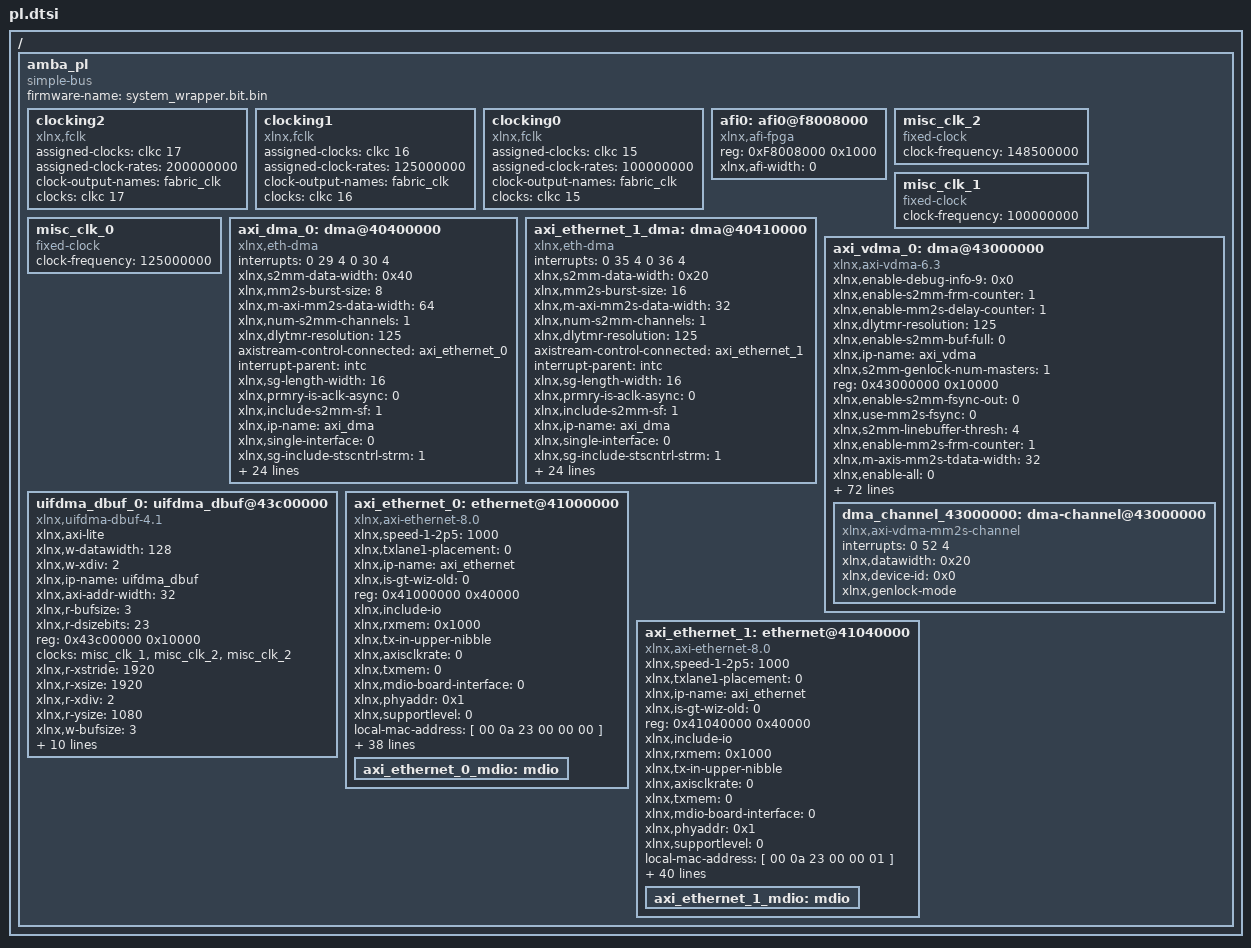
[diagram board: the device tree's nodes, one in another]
/ {
	amba_pl: amba_pl {
		ranges;
		compatible = "simple-bus";
		#address-cells = <1>;
		#size-cells = <1>;
		firmware-name = "system_wrapper.bit.bin";
		clocking2: clocking2 {
			compatible = "xlnx,fclk";
			assigned-clocks = <&clkc 17>;
			assigned-clock-rates = <200000000>;
			#clock-cells = <0>;
			clock-output-names = "fabric_clk";
			clocks = <&clkc 17>;
		};
		clocking1: clocking1 {
			compatible = "xlnx,fclk";
			assigned-clocks = <&clkc 16>;
			assigned-clock-rates = <125000000>;
			#clock-cells = <0>;
			clock-output-names = "fabric_clk";
			clocks = <&clkc 16>;
		};
		clocking0: clocking0 {
			compatible = "xlnx,fclk";
			assigned-clocks = <&clkc 15>;
			assigned-clock-rates = <100000000>;
			#clock-cells = <0>;
			clock-output-names = "fabric_clk";
			clocks = <&clkc 15>;
		};
		afi0: afi0@f8008000 {
			status = "okay";
			compatible = "xlnx,afi-fpga";
			#address-cells = <1>;
			reg = <0xF8008000 0x1000>;
			#size-cells = <0>;
			xlnx,afi-width = <0>;
		};
		misc_clk_2: misc_clk_2 {
			compatible = "fixed-clock";
			clock-frequency = <148500000>;
			#clock-cells = <0>;
		};
		misc_clk_1: misc_clk_1 {
			compatible = "fixed-clock";
			clock-frequency = <100000000>;
			#clock-cells = <0>;
		};
		misc_clk_0: misc_clk_0 {
			compatible = "fixed-clock";
			clock-frequency = <125000000>;
			#clock-cells = <0>;
		};
		axi_dma_0: dma@40400000 {
			interrupts = < 0 29 4 0 30 4 >;
			compatible = "xlnx,eth-dma";
			xlnx,s2mm-data-width = <0x40>;
			xlnx,mm2s-burst-size = <8>;
			xlnx,m-axi-mm2s-data-width = <64>;
			xlnx,num-s2mm-channels = <1>;
			xlnx,dlytmr-resolution = <125>;
			axistream-control-connected = <&axi_ethernet_0>;
			interrupt-parent = <&intc>;
			xlnx,sg-length-width = <16>;
			xlnx,prmry-is-aclk-async = <0>;
			xlnx,include-s2mm-sf = <1>;
			#dma-cells = <1>;
			xlnx,ip-name = "axi_dma";
			xlnx,single-interface = <0>;
			xlnx,sg-include-stscntrl-strm = <1>;
			xlnx,include-s2mm-dre = <1>;
			reg = <0x40400000 0x10000>;
			xlnx,addr-width = <32>;
			xlnx,include-s2mm = <1>;
			clocks = <&clkc 15>, <&clkc 15>, <&clkc 15>, <&clkc 15>;
			xlnx,s-axis-s2mm-tdata-width = <32>;
			xlnx,micro-dma = <0>;
			xlnx,increase-throughput = <0>;
			xlnx,mm2s-data-width = <0x40>;
			xlnx,addrwidth = <0x20>;
			xlnx,sg-use-stsapp-length = <1>;
			xlnx,m-axis-mm2s-tdata-width = <32>;
			xlnx,include-dre;
			xlnx,edk-iptype = "PERIPHERAL";
			xlnx,s2mm-burst-size = <16>;
			xlnx,m-axi-s2mm-data-width = <64>;
			xlnx,num-queues = /bits/ 16 <0x1>;
			xlnx,num-mm2s-channels = <1>;
			xlnx,enable-multi-channel = <0>;
			status = "okay";
			xlnx,include-mm2s-sf = <1>;
			clock-names = "m_axi_mm2s_aclk" , "m_axi_s2mm_aclk" , "m_axi_sg_aclk" , "s_axi_lite_aclk";
			axistream-connected = <&axi_ethernet_0>;
			interrupt-names = "mm2s_introut" , "s2mm_introut";
			xlnx,include-mm2s = <1>;
			xlnx,include-mm2s-dre = <1>;
			xlnx,name = "axi_dma_0";
		};
		axi_ethernet_1_dma: dma@40410000 {
			interrupts = < 0 35 4 0 36 4 >;
			compatible = "xlnx,eth-dma";
			xlnx,s2mm-data-width = <0x20>;
			xlnx,mm2s-burst-size = <16>;
			xlnx,m-axi-mm2s-data-width = <32>;
			xlnx,num-s2mm-channels = <1>;
			xlnx,dlytmr-resolution = <125>;
			axistream-control-connected = <&axi_ethernet_1>;
			interrupt-parent = <&intc>;
			xlnx,sg-length-width = <16>;
			xlnx,prmry-is-aclk-async = <0>;
			xlnx,include-s2mm-sf = <1>;
			#dma-cells = <1>;
			xlnx,ip-name = "axi_dma";
			xlnx,single-interface = <0>;
			xlnx,sg-include-stscntrl-strm = <1>;
			xlnx,include-s2mm-dre = <1>;
			reg = <0x40410000 0x10000>;
			xlnx,addr-width = <32>;
			xlnx,include-s2mm = <1>;
			clocks = <&clkc 15>, <&clkc 15>, <&clkc 15>, <&clkc 15>;
			xlnx,s-axis-s2mm-tdata-width = <32>;
			xlnx,micro-dma = <0>;
			xlnx,increase-throughput = <0>;
			xlnx,mm2s-data-width = <0x20>;
			xlnx,addrwidth = <0x20>;
			xlnx,sg-use-stsapp-length = <1>;
			xlnx,m-axis-mm2s-tdata-width = <32>;
			xlnx,include-dre;
			xlnx,edk-iptype = "PERIPHERAL";
			xlnx,s2mm-burst-size = <16>;
			xlnx,m-axi-s2mm-data-width = <32>;
			xlnx,num-queues = /bits/ 16 <0x1>;
			xlnx,num-mm2s-channels = <1>;
			xlnx,enable-multi-channel = <0>;
			status = "okay";
			xlnx,include-mm2s-sf = <1>;
			clock-names = "m_axi_mm2s_aclk" , "m_axi_s2mm_aclk" , "m_axi_sg_aclk" , "s_axi_lite_aclk";
			axistream-connected = <&axi_ethernet_1>;
			interrupt-names = "mm2s_introut" , "s2mm_introut";
			xlnx,include-mm2s = <1>;
			xlnx,include-mm2s-dre = <1>;
			xlnx,name = "axi_ethernet_1_dma";
		};
		axi_vdma_0: dma@43000000 {
			xlnx,enable-debug-info-9 = <0x0>;
			xlnx,enable-s2mm-frm-counter = <1>;
			xlnx,enable-mm2s-delay-counter = <1>;
			xlnx,dlytmr-resolution = <125>;
			xlnx,enable-s2mm-buf-full = <0>;
			xlnx,ip-name = "axi_vdma";
			xlnx,s2mm-genlock-num-masters = <1>;
			reg = <0x43000000 0x10000>;
			xlnx,enable-s2mm-fsync-out = <0>;
			xlnx,use-mm2s-fsync = <0>;
			xlnx,s2mm-linebuffer-thresh = <4>;
			xlnx,enable-mm2s-frm-counter = <1>;
			xlnx,m-axis-mm2s-tdata-width = <32>;
			xlnx,enable-all = <0>;
			xlnx,dynamic-resolution = <1>;
			xlnx,enable-s2mm-rst-out = <0>;
			interrupt-names = "mm2s_introut";
			xlnx,s2mm-sof-enable = <0x1>;
			xlnx,mm2s-genlock-num-masters = <1>;
			xlnx,enable-mm2s-fsync-out = <0>;
			xlnx,mm2s-linebuffer-thresh = <4>;
			compatible = "xlnx,axi-vdma-6.3" , "xlnx,axi-vdma-1.00.a";
			xlnx,enable-tstvec = <0>;
			interrupt-parent = <&intc>;
			xlnx,s2mm-max-burst-length = <8>;
			xlnx,enable-mm2s-rst-out = <0>;
			xlnx,mm2s-sof-enable = <1>;
			xlnx,include-s2mm-dre = <0x0>;
			xlnx,enable-s2mm-frmstr-reg = <0>;
			xlnx,m-axi-s2mm-data-width = <64>;
			xlnx,enable-s2mm-sts-reg = <0>;
			xlnx,mm2s-max-burst-length = <64>;
			status = "okay";
			xlnx,include-mm2s-dre = <0x0>;
			xlnx,name = "axi_vdma_0";
			xlnx,enable-mm2s-frmstr-reg = <0>;
			interrupts = < 0 52 4 >;
			xlnx,m-axi-mm2s-data-width = <64>;
			xlnx,flush-on-fsync = <0x1>;
			xlnx,include-s2mm-sf = <1>;
			xlnx,single-interface = <0>;
			xlnx,s2mm-linebuffer-depth = <0x200>;
			xlnx,include-s2mm = <0x0>;
			xlnx,addr-width = <64>;
			clocks = <&clkc 15>, <&clkc 15>, <&clkc 15>;
			xlnx,s-axis-s2mm-tdata-width = <32>;
			xlnx,enable-debug-info-10 = <0>;
			xlnx,addrwidth = <0x40>;
			xlnx,enable-debug-info-11 = <0>;
			xlnx,edk-iptype = "PERIPHERAL";
			xlnx,enable-debug-info-12 = <0>;
			xlnx,use-fsync = <1>;
			xlnx,s2mm-genlock-repeat-en = <1>;
			xlnx,enable-debug-info-13 = <0x0>;
			xlnx,enable-vert-flip = <0x0>;
			xlnx,include-mm2s-sf = <0>;
			xlnx,enable-debug-info-14 = <0x1>;
			xlnx,include-internal-genlock = <0x1>;
			clock-names = "m_axi_mm2s_aclk" , "m_axis_mm2s_aclk" , "s_axi_lite_aclk";
			xlnx,enable-debug-info-15 = <0x1>;
			xlnx,mm2s-linebuffer-depth = <0x800>;
			xlnx,include-mm2s = <0x1>;
			xlnx,s2mm-genlock-mode = <0x0>;
			xlnx,flush-fsync = <0x1>;
			xlnx,select-xpm = <0>;
			xlnx,s2mm-data-width = <0x40>;
			xlnx,num-fstores = <0x1>;
			xlnx,enable-s2mm-param-updt = <0>;
			xlnx,enable-vidparam-reads = <0x1>;
			xlnx,mm2s-genlock-repeat-en = <0>;
			xlnx,prmry-is-aclk-async = <0>;
			xlnx,s2mm-tdata-width = <0x20>;
			#dma-cells = <1>;
			xlnx,enable-vidprmtr-reads = <1>;
			xlnx,mm2s-genlock-mode = <0x1>;
			xlnx,enable-debug-info-0 = <0>;
			xlnx,enable-debug-all = <0x0>;
			xlnx,enable-debug-info-1 = <0x0>;
			xlnx,mm2s-data-width = <0x40>;
			xlnx,enable-debug-info-2 = <0>;
			xlnx,enable-mm2s-param-updt = <0>;
			xlnx,enable-debug-info-3 = <0>;
			xlnx,enable-s2mm-delay-counter = <1>;
			xlnx,enable-debug-info-4 = <0>;
			xlnx,enable-debug-info-5 = <0x0>;
			xlnx,mm2s-tdata-width = <0x20>;
			xlnx,enable-debug-info-6 = <0x1>;
			xlnx,enable-debug-info-7 = <0x1>;
			xlnx,use-s2mm-fsync = <2>;
			xlnx,enable-debug-info-8 = <0>;
			xlnx,enable-mm2s-buf-empty = <0>;
			dma_channel_43000000: dma-channel@43000000 {
				interrupts = < 0 52 4 >;
				xlnx,datawidth = <0x20>;
				xlnx,device-id = <0x0>;
				compatible = "xlnx,axi-vdma-mm2s-channel";
				xlnx,genlock-mode;
			};
		};
		uifdma_dbuf_0: uifdma_dbuf@43c00000 {
			compatible = "xlnx,uifdma-dbuf-4.1";
			xlnx,axi-lite;
			xlnx,w-datawidth = <128>;
			xlnx,w-xdiv = <2>;
			xlnx,ip-name = "uifdma_dbuf";
			xlnx,axi-addr-width = <32>;
			xlnx,r-bufsize = <3>;
			xlnx,r-dsizebits = <23>;
			reg = <0x43c00000 0x10000>;
			clocks = <&misc_clk_1>, <&misc_clk_2>, <&misc_clk_2>;
			xlnx,r-xstride = <1920>;
			xlnx,r-xsize = <1920>;
			xlnx,r-xdiv = <2>;
			xlnx,r-ysize = <1080>;
			xlnx,w-bufsize = <3>;
			xlnx,edk-iptype = "PERIPHERAL";
			xlnx,w-dsizebits = <23>;
			xlnx,w-bufdepth = <2048>;
			status = "okay";
			xlnx,axi-data-width = <128>;
			clock-names = "I_R_rclk" , "I_W_wclk" , "S_AXI_ACLK";
			xlnx,w-xstride = <1920>;
			xlnx,w-xsize = <1920>;
			xlnx,w-ysize = <1080>;
			xlnx,name = "uifdma_dbuf_0";
			xlnx,r-bufdepth = <64>;
			xlnx,r-datawidth = <32>;
		};
		axi_ethernet_0: ethernet@41000000 {
			xlnx,speed-1-2p5 = <1000>;
			xlnx,txlane1-placement = "0";
			xlnx,ip-name = "axi_ethernet";
			xlnx,is-gt-wiz-old = <0>;
			reg = <0x41000000 0x40000>;
			xlnx,include-io;
			xlnx,rxmem = <0x1000>;
			xlnx,tx-in-upper-nibble;
			xlnx,axisclkrate = <0>;
			xlnx,txmem = "0";
			xlnx,mdio-board-interface = "0";
			xlnx,phyaddr = <0x1>;
			xlnx,supportlevel = <0>;
			local-mac-address = [ 00 0a 23 00 00 00 ];
			xlnx,diffclk-board-interface = "0";
			xlnx,frame-filter;
			axistream-connected = <&axi_dma_0>;
			xlnx,phyrst-board-interface-dummy-port = "0";
			interrupt-names = "interrupt" , "mac_irq" , "mm2s_introut" , "s2mm_introut";
			compatible = "xlnx,axi-ethernet-8.0" , "xlnx,axi-ethernet-1.00.a" , "xlnx,axi-ethernet-1.00.a";
			xlnx,gt-type = "0";
			xlnx,drpclkrate = <0>;
			axistream-control-connected = <&axi_dma_0>;
			interrupt-parent = <&intc>;
			xlnx,versal-gt-board-flow = <0>;
			xlnx,num-queues = /bits/ 16 <0x1>;
			xlnx,channel-ids = < 1 >;
			max-speed = <1000>;
			status = "okay";
			xlnx,timer-format = <0>;
			xlnx,statistics-width = "0";
			xlnx,name = "axi_ethernet_0";
			interrupts = < 0 32 4 0 31 1 0 29 4 0 30 4 >;
			clocks = <&clkc 15>, <&clkc 16>, <&clkc 17>, <&clkc 15>;
			xlnx,gtrefclksrc = "0";
			xlnx,rxcsum = <0x0>;
			xlnx,statistics-counters;
			xlnx,include-dre;
			xlnx,edk-iptype = "0";
			xlnx,gtrefclkrate = <0>;
			xlnx,lvdsclkrate = <0>;
			xlnx,number-of-table-entries = <0>;
			clock-names = "axis_clk" , "gtx_clk" , "ref_clk" , "s_axi_lite_clk";
			xlnx,rxlane0-placement = "0";
			xlnx,timer-clk-period = <0>;
			xlnx,ethernet-board-interface = "0";
			xlnx,txlane0-placement = "0";
			xlnx,gtlocation = "0";
			phy-mode = "rgmii";
			xlnx,gt-settings = <0>;
			xlnx,clockselection = "0";
			xlnx,processor-mode;
			xlnx,txcsum = <0x0>;
			xlnx,phyrst-board-interface = "0";
			xlnx,axiliteclkrate = <0>;
			xlnx,rxlane1-placement = "0";
			axi_ethernet_0_mdio: mdio {
				#address-cells = <1>;
				#size-cells = <0>;
			};
		};
		axi_ethernet_1: ethernet@41040000 {
			xlnx,speed-1-2p5 = <1000>;
			xlnx,txlane1-placement = "0";
			xlnx,ip-name = "axi_ethernet";
			xlnx,is-gt-wiz-old = <0>;
			reg = <0x41040000 0x40000>;
			xlnx,include-io;
			xlnx,rxmem = <0x1000>;
			xlnx,tx-in-upper-nibble;
			xlnx,axisclkrate = <0>;
			xlnx,txmem = "0";
			xlnx,mdio-board-interface = "0";
			xlnx,phyaddr = <0x1>;
			xlnx,supportlevel = <0>;
			local-mac-address = [ 00 0a 23 00 00 01 ];
			xlnx,diffclk-board-interface = "0";
			xlnx,frame-filter;
			axistream-connected = <&axi_ethernet_1_dma>;
			xlnx,phyrst-board-interface-dummy-port = "0";
			interrupt-names = "interrupt" , "mac_irq" , "mm2s_introut" , "s2mm_introut";
			compatible = "xlnx,axi-ethernet-8.0" , "xlnx,axi-ethernet-1.00.a" , "xlnx,axi-ethernet-1.00.a";
			xlnx,gt-type = "0";
			xlnx,drpclkrate = <0>;
			axistream-control-connected = <&axi_ethernet_1_dma>;
			interrupt-parent = <&intc>;
			xlnx,versal-gt-board-flow = <0>;
			xlnx,num-queues = /bits/ 16 <0x1>;
			xlnx,channel-ids = < 1 >;
			max-speed = <1000>;
			status = "okay";
			xlnx,timer-format = <0>;
			xlnx,statistics-width = "0";
			xlnx,name = "axi_ethernet_1";
			interrupts = < 0 34 4 0 33 1 0 35 4 0 36 4 >;
			clocks = <&clkc 15>, <&misc_clk_0>, <&misc_clk_0>, <&clkc 15>;
			xlnx,gtrefclksrc = "0";
			xlnx,rxcsum = <0x0>;
			xlnx,statistics-counters;
			xlnx,include-dre;
			xlnx,edk-iptype = "0";
			xlnx,gtrefclkrate = <0>;
			xlnx,lvdsclkrate = <0>;
			xlnx,number-of-table-entries = <0>;
			clock-names = "axis_clk" , "gtx_clk" , "gtx_clk90" , "s_axi_lite_clk";
			xlnx,rxlane0-placement = "0";
			xlnx,timer-clk-period = <0>;
			xlnx,ethernet-board-interface = "0";
			xlnx,txlane0-placement = "0";
			xlnx,gtlocation = "0";
			phy-mode = "rgmii";
			xlnx,gt-settings = <0>;
			xlnx,clockselection = "0";
			xlnx,processor-mode;
			xlnx,txcsum = <0x0>;
			xlnx,phyrst-board-interface = "0";
			xlnx,axiliteclkrate = <0>;
			xlnx,rxlane1-placement = "0";
			axi_ethernet_1_mdio: mdio {
				#address-cells = <1>;
				#size-cells = <0>;
			};
		};
	};
};
